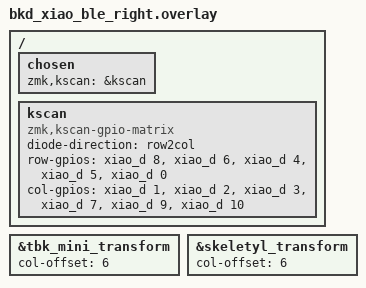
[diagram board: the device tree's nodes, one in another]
/*
 * Copyright (c) 2022 The ZMK Contributors
 *
 * SPDX-License-Identifier: MIT
 */

#include "bkd_xiao_ble.dtsi"

&tbk_mini_transform {
	col-offset = <6>;
};

&skeletyl_transform {
	col-offset = <6>;
};

/ {
	chosen {
		zmk,kscan = &kscan;
	};

	kscan: kscan {
		compatible = "zmk,kscan-gpio-matrix";
		diode-direction = "row2col";

		row-gpios
			= <&xiao_d 8 (GPIO_ACTIVE_HIGH)>
			, <&xiao_d 6 (GPIO_ACTIVE_HIGH)>
			, <&xiao_d 4 (GPIO_ACTIVE_HIGH)>
			, <&xiao_d 5 (GPIO_ACTIVE_HIGH)>
			, <&xiao_d 0 (GPIO_ACTIVE_HIGH)>
			;

		col-gpios
			= <&xiao_d 1 (GPIO_ACTIVE_HIGH | GPIO_PULL_DOWN)>
			, <&xiao_d 2 (GPIO_ACTIVE_HIGH | GPIO_PULL_DOWN)>
			, <&xiao_d 3 (GPIO_ACTIVE_HIGH | GPIO_PULL_DOWN)>
			, <&xiao_d 7 (GPIO_ACTIVE_HIGH | GPIO_PULL_DOWN)>
			, <&xiao_d 9 (GPIO_ACTIVE_HIGH | GPIO_PULL_DOWN)>
			, <&xiao_d 10 (GPIO_ACTIVE_HIGH | GPIO_PULL_DOWN)>
			;
	};
};
